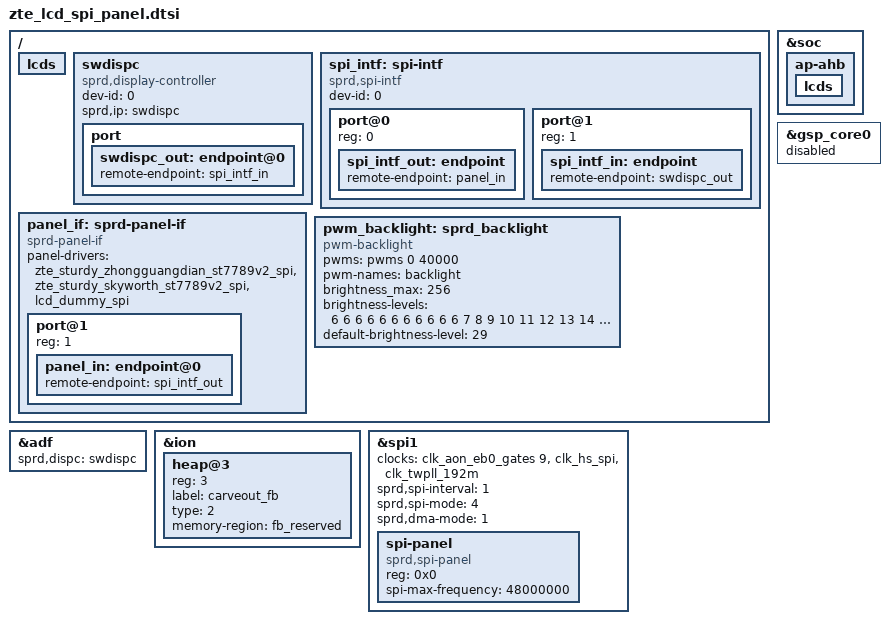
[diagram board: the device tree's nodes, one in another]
#include "lcd/lcd_dummy_spi.dtsi"
#include "zte_sturdy_zhongguangdian_st7789v2_spi.dtsi"
#include "zte_sturdy_skyworth_st7789v2_spi.dtsi"

&soc {
	ap-ahb {
		/delete-node/ dispc@20800000;
		/delete-node/ dsi@21800000;
		/delete-node/ dphy@0;
		lcds {
			/delete-node/ lcdffff@0;
		};
	};
};

/ {
	lcds {
		/delete-node/ lcd77012@77012;
		/delete-node/ lcd9503@9503;
		/delete-node/ lcd91613@91613;
		/delete-node/ lcd9881@9881;
	};
	swdispc: swdispc {
		compatible = "sprd,display-controller";
		dev-id = <0>;
		status = "okay";

		sprd,ip = "swdispc";
					/* output port */
		port {
			swdispc_out: endpoint@0 {

				remote-endpoint = <&spi_intf_in>;
			};
		};
	};

	spi_intf: spi-intf {
		compatible = "sprd,spi-intf";
		#address-cells = <1>;
		#size-cells = <0>;
		dev-id = <0>;
		status = "okay";
		/* output port */
		port@0 {
			reg = <0>;
			spi_intf_out: endpoint {
				remote-endpoint = <&panel_in>;
			};
		};

					/* input port */
		port@1 {
			reg = <1>;
			spi_intf_in: endpoint {
				remote-endpoint = <&swdispc_out>;
			};
		};
	};

	panel_if: sprd-panel-if {
		compatible = "sprd-panel-if";
		#address-cells = <1>;
		#size-cells = <0>;
		panel-drivers = <
			&zte_sturdy_zhongguangdian_st7789v2_spi
			&zte_sturdy_skyworth_st7789v2_spi
			&lcd_dummy_spi
		>;
		/* input port */
		port@1 {
				/* WARNING: the reg property must be 1 ! */
				reg = <1>;
				panel_in: endpoint@0 {
				remote-endpoint = <&spi_intf_out>;
			};
		};
	};

	pwm_backlight: sprd_backlight {
		compatible = "pwm-backlight";
		status = "okay";
		pwms = <&pwms 0 40000>;
		pwm-names = "backlight";
		brightness_max = <256>;
		brightness-levels = <
						6   6   6   6
			 6   6   6   6   6   6   6   7   8   9
			10  11  12  13  14  15  16  17  18  19
			20  21  22  23  24  25  26  27  28  29
			30  31  32  33  34  35  36  37  38  39
			40  41  42  43  44  45  46  47  48  49
			50  51  52  53  54  55  56  57  58  59
			60  61  62  63  64  65  66  67  68  69
			70  71  72  73  74  75  76  77  78  79
			80  81  82  83  84  85  86  87  88  89
			90  91  92  93  94  95  96  97  98  99
			100 101 102 103 104 105 106 107 108 109
			110 111 112 113 114 115 116 117 118 119
			120 121 122 123 124 125 126 127 128 129
			130 131 132 133 134 135 136 137 138 139
			140 141 142 143 144 145 146 147 148 149
			150 151 152 153 154 155 156 157 158 159
			160 161 162 163 164 165 166 167 168 169
			170 171 172 173 174 175 176 177 178 179
			180 181 182 183 184 185 186 187 188 189
			190 191 192 193 194 195 196 197 198 199
			200 201 202 203 204 205 206 207 208 209
			210 211 212 213 214 215 216 217 218 219
			220 221 222 223 224 225 226 227 228 229
			230 231 232 233 234 235 236 237 238 239
			240 241 242 243 244 245 246 247 248 249
			250 251
			>;
		default-brightness-level = <29>;
	};

};
&adf {
	sprd,dispc = <&swdispc>;
};

&ion {
	heap@3 {
		reg = <3>;
		label = "carveout_fb";
		type = <2>;
		memory-region = <&fb_reserved>;
	};
};
&spi1 {
	clocks = <&clk_aon_eb0_gates 9>, <&clk_hs_spi>, <&clk_twpll_192m>;
	status = "okay";
	sprd,spi-interval = <1>;
	sprd,spi-mode = <4>;
	sprd,dma-mode = <1>;
	spi-panel {
		compatible = "sprd,spi-panel";
		reg = <0x0>;
		spi-max-frequency = <48000000>;
	};
};
&gsp_core0 {
	status = "disable";
};

